VERSION ""

NS_ :

BS_:

BU_: NFCReader_Interior SCU NFCReader_Exterior

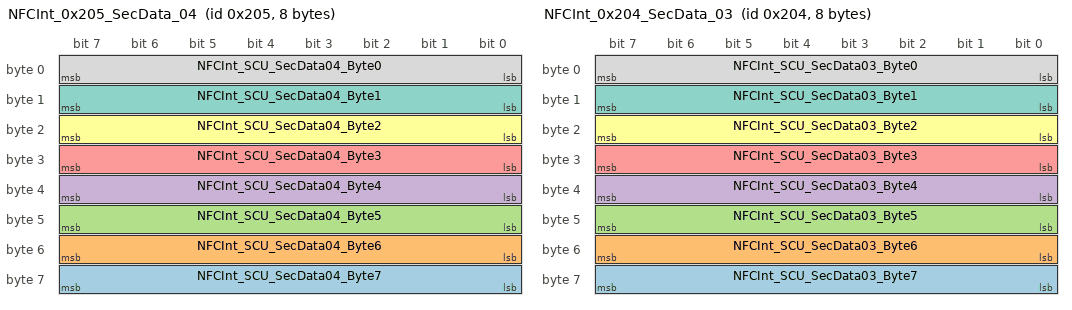
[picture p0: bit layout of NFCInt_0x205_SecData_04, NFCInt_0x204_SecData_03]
BO_ 517 NFCInt_0x205_SecData_04: 8 NFCReader_Interior
 SG_ NFCInt_SCU_SecData04_Byte7 : 56|8@1+ (1,0) [0|0] ""  SCU
 SG_ NFCInt_SCU_SecData04_Byte6 : 48|8@1+ (1,0) [0|0] ""  SCU
 SG_ NFCInt_SCU_SecData04_Byte5 : 40|8@1+ (1,0) [0|0] ""  SCU
 SG_ NFCInt_SCU_SecData04_Byte4 : 32|8@1+ (1,0) [0|0] ""  SCU
 SG_ NFCInt_SCU_SecData04_Byte3 : 24|8@1+ (1,0) [0|0] ""  SCU
 SG_ NFCInt_SCU_SecData04_Byte2 : 16|8@1+ (1,0) [0|0] ""  SCU
 SG_ NFCInt_SCU_SecData04_Byte1 : 8|8@1+ (1,0) [0|0] ""  SCU
 SG_ NFCInt_SCU_SecData04_Byte0 : 0|8@1+ (1,0) [0|0] ""  SCU

BO_ 516 NFCInt_0x204_SecData_03: 8 NFCReader_Interior
 SG_ NFCInt_SCU_SecData03_Byte7 : 56|8@1+ (1,0) [0|0] ""  SCU
 SG_ NFCInt_SCU_SecData03_Byte6 : 48|8@1+ (1,0) [0|0] ""  SCU
 SG_ NFCInt_SCU_SecData03_Byte5 : 40|8@1+ (1,0) [0|0] ""  SCU
 SG_ NFCInt_SCU_SecData03_Byte4 : 32|8@1+ (1,0) [0|0] ""  SCU
 SG_ NFCInt_SCU_SecData03_Byte3 : 24|8@1+ (1,0) [0|0] ""  SCU
 SG_ NFCInt_SCU_SecData03_Byte2 : 16|8@1+ (1,0) [0|0] ""  SCU
 SG_ NFCInt_SCU_SecData03_Byte1 : 8|8@1+ (1,0) [0|0] ""  SCU
 SG_ NFCInt_SCU_SecData03_Byte0 : 0|8@1+ (1,0) [0|0] ""  SCU

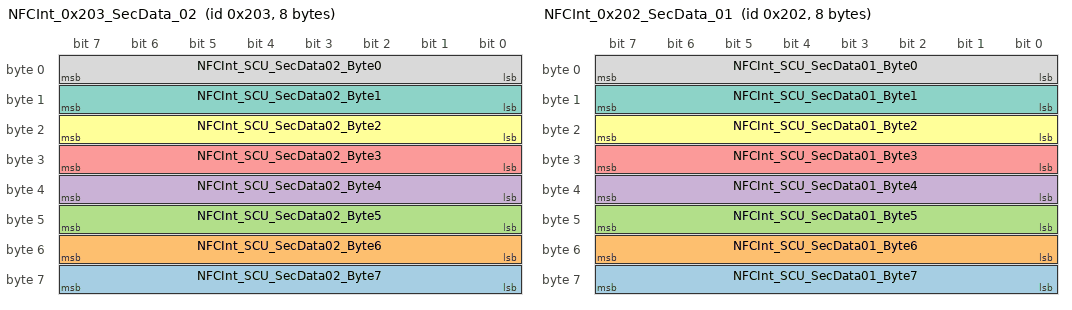
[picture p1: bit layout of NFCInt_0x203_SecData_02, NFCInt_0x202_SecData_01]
BO_ 515 NFCInt_0x203_SecData_02: 8 NFCReader_Interior
 SG_ NFCInt_SCU_SecData02_Byte7 : 56|8@1+ (1,0) [0|0] ""  SCU
 SG_ NFCInt_SCU_SecData02_Byte6 : 48|8@1+ (1,0) [0|0] ""  SCU
 SG_ NFCInt_SCU_SecData02_Byte5 : 40|8@1+ (1,0) [0|0] ""  SCU
 SG_ NFCInt_SCU_SecData02_Byte4 : 32|8@1+ (1,0) [0|0] ""  SCU
 SG_ NFCInt_SCU_SecData02_Byte3 : 24|8@1+ (1,0) [0|0] ""  SCU
 SG_ NFCInt_SCU_SecData02_Byte2 : 16|8@1+ (1,0) [0|0] ""  SCU
 SG_ NFCInt_SCU_SecData02_Byte1 : 8|8@1+ (1,0) [0|0] ""  SCU
 SG_ NFCInt_SCU_SecData02_Byte0 : 0|8@1+ (1,0) [0|0] ""  SCU

BO_ 514 NFCInt_0x202_SecData_01: 8 NFCReader_Interior
 SG_ NFCInt_SCU_SecData01_Byte7 : 56|8@1+ (1,0) [0|0] ""  SCU
 SG_ NFCInt_SCU_SecData01_Byte6 : 48|8@1+ (1,0) [0|0] ""  SCU
 SG_ NFCInt_SCU_SecData01_Byte5 : 40|8@1+ (1,0) [0|0] ""  SCU
 SG_ NFCInt_SCU_SecData01_Byte4 : 32|8@1+ (1,0) [0|0] ""  SCU
 SG_ NFCInt_SCU_SecData01_Byte3 : 24|8@1+ (1,0) [0|0] ""  SCU
 SG_ NFCInt_SCU_SecData01_Byte2 : 16|8@1+ (1,0) [0|0] ""  SCU
 SG_ NFCInt_SCU_SecData01_Byte1 : 8|8@1+ (1,0) [0|0] ""  SCU
 SG_ NFCInt_SCU_SecData01_Byte0 : 0|8@1+ (1,0) [0|0] ""  SCU

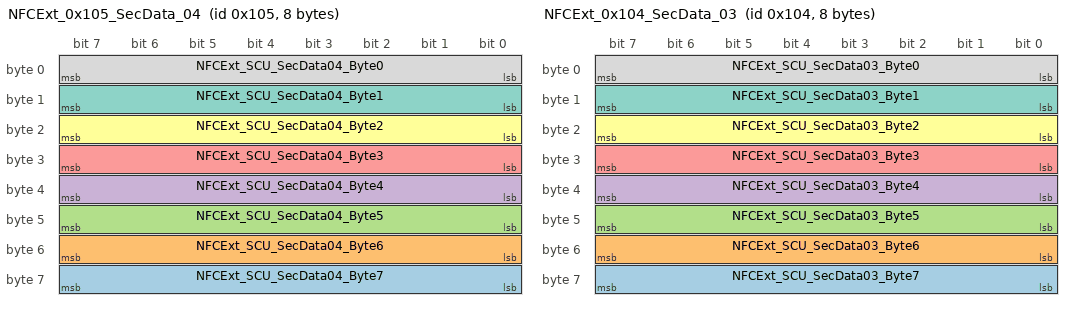
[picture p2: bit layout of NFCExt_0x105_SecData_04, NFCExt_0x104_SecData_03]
BO_ 261 NFCExt_0x105_SecData_04: 8 NFCReader_Exterior
 SG_ NFCExt_SCU_SecData04_Byte7 : 56|8@1+ (1,0) [0|0] ""  SCU
 SG_ NFCExt_SCU_SecData04_Byte6 : 48|8@1+ (1,0) [0|0] ""  SCU
 SG_ NFCExt_SCU_SecData04_Byte5 : 40|8@1+ (1,0) [0|0] ""  SCU
 SG_ NFCExt_SCU_SecData04_Byte4 : 32|8@1+ (1,0) [0|0] ""  SCU
 SG_ NFCExt_SCU_SecData04_Byte3 : 24|8@1+ (1,0) [0|0] ""  SCU
 SG_ NFCExt_SCU_SecData04_Byte2 : 16|8@1+ (1,0) [0|0] ""  SCU
 SG_ NFCExt_SCU_SecData04_Byte1 : 8|8@1+ (1,0) [0|0] ""  SCU
 SG_ NFCExt_SCU_SecData04_Byte0 : 0|8@1+ (1,0) [0|0] ""  SCU

BO_ 260 NFCExt_0x104_SecData_03: 8 NFCReader_Exterior
 SG_ NFCExt_SCU_SecData03_Byte7 : 56|8@1+ (1,0) [0|0] ""  SCU
 SG_ NFCExt_SCU_SecData03_Byte6 : 48|8@1+ (1,0) [0|0] ""  SCU
 SG_ NFCExt_SCU_SecData03_Byte5 : 40|8@1+ (1,0) [0|0] ""  SCU
 SG_ NFCExt_SCU_SecData03_Byte4 : 32|8@1+ (1,0) [0|0] ""  SCU
 SG_ NFCExt_SCU_SecData03_Byte3 : 24|8@1+ (1,0) [0|0] ""  SCU
 SG_ NFCExt_SCU_SecData03_Byte2 : 16|8@1+ (1,0) [0|0] ""  SCU
 SG_ NFCExt_SCU_SecData03_Byte1 : 8|8@1+ (1,0) [0|0] ""  SCU
 SG_ NFCExt_SCU_SecData03_Byte0 : 0|8@1+ (1,0) [0|0] ""  SCU

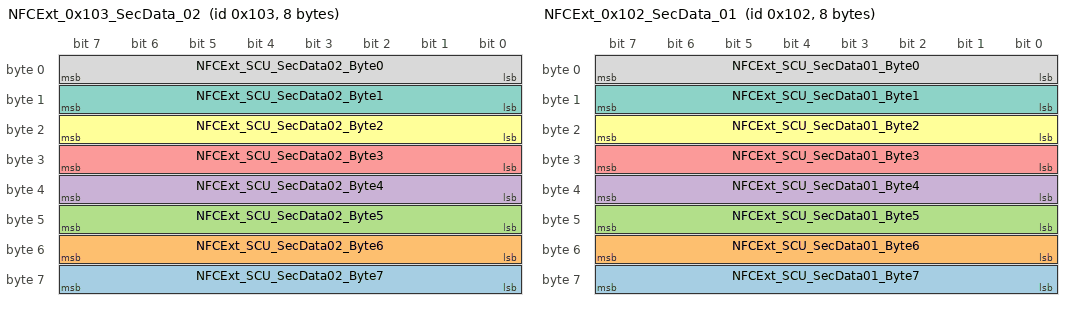
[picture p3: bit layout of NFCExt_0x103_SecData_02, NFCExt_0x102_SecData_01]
BO_ 259 NFCExt_0x103_SecData_02: 8 NFCReader_Exterior
 SG_ NFCExt_SCU_SecData02_Byte7 : 56|8@1+ (1,0) [0|0] ""  SCU
 SG_ NFCExt_SCU_SecData02_Byte6 : 48|8@1+ (1,0) [0|0] ""  SCU
 SG_ NFCExt_SCU_SecData02_Byte5 : 40|8@1+ (1,0) [0|0] ""  SCU
 SG_ NFCExt_SCU_SecData02_Byte4 : 32|8@1+ (1,0) [0|0] ""  SCU
 SG_ NFCExt_SCU_SecData02_Byte3 : 24|8@1+ (1,0) [0|0] ""  SCU
 SG_ NFCExt_SCU_SecData02_Byte2 : 16|8@1+ (1,0) [0|0] ""  SCU
 SG_ NFCExt_SCU_SecData02_Byte1 : 8|8@1+ (1,0) [0|0] ""  SCU
 SG_ NFCExt_SCU_SecData02_Byte0 : 0|8@1+ (1,0) [0|0] ""  SCU

BO_ 258 NFCExt_0x102_SecData_01: 8 NFCReader_Exterior
 SG_ NFCExt_SCU_SecData01_Byte7 : 56|8@1+ (1,0) [0|0] ""  SCU
 SG_ NFCExt_SCU_SecData01_Byte6 : 48|8@1+ (1,0) [0|0] ""  SCU
 SG_ NFCExt_SCU_SecData01_Byte5 : 40|8@1+ (1,0) [0|0] ""  SCU
 SG_ NFCExt_SCU_SecData01_Byte4 : 32|8@1+ (1,0) [0|0] ""  SCU
 SG_ NFCExt_SCU_SecData01_Byte3 : 24|8@1+ (1,0) [0|0] ""  SCU
 SG_ NFCExt_SCU_SecData01_Byte2 : 16|8@1+ (1,0) [0|0] ""  SCU
 SG_ NFCExt_SCU_SecData01_Byte1 : 8|8@1+ (1,0) [0|0] ""  SCU
 SG_ NFCExt_SCU_SecData01_Byte0 : 0|8@1+ (1,0) [0|0] ""  SCU

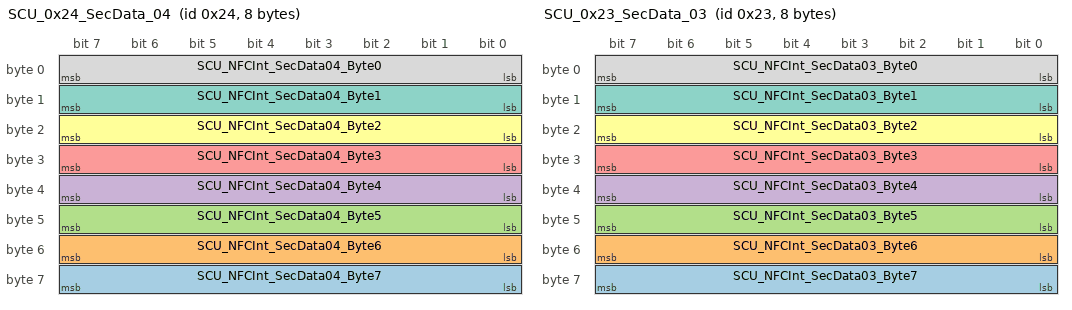
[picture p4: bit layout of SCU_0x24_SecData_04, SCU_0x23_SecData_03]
BO_ 36 SCU_0x24_SecData_04: 8 SCU
 SG_ SCU_NFCInt_SecData04_Byte7 : 56|8@1+ (1,0) [0|0] ""  NFCReader_Interior
 SG_ SCU_NFCInt_SecData04_Byte6 : 48|8@1+ (1,0) [0|0] ""  NFCReader_Interior
 SG_ SCU_NFCInt_SecData04_Byte5 : 40|8@1+ (1,0) [0|0] ""  NFCReader_Interior
 SG_ SCU_NFCInt_SecData04_Byte4 : 32|8@1+ (1,0) [0|0] ""  NFCReader_Interior
 SG_ SCU_NFCInt_SecData04_Byte3 : 24|8@1+ (1,0) [0|0] ""  NFCReader_Interior
 SG_ SCU_NFCInt_SecData04_Byte2 : 16|8@1+ (1,0) [0|0] ""  NFCReader_Interior
 SG_ SCU_NFCInt_SecData04_Byte1 : 8|8@1+ (1,0) [0|0] ""  NFCReader_Interior
 SG_ SCU_NFCInt_SecData04_Byte0 : 0|8@1+ (1,0) [0|0] ""  NFCReader_Interior

BO_ 35 SCU_0x23_SecData_03: 8 SCU
 SG_ SCU_NFCInt_SecData03_Byte7 : 56|8@1+ (1,0) [0|0] ""  NFCReader_Interior
 SG_ SCU_NFCInt_SecData03_Byte6 : 48|8@1+ (1,0) [0|0] ""  NFCReader_Interior
 SG_ SCU_NFCInt_SecData03_Byte5 : 40|8@1+ (1,0) [0|0] ""  NFCReader_Interior
 SG_ SCU_NFCInt_SecData03_Byte4 : 32|8@1+ (1,0) [0|0] ""  NFCReader_Interior
 SG_ SCU_NFCInt_SecData03_Byte3 : 24|8@1+ (1,0) [0|0] ""  NFCReader_Interior
 SG_ SCU_NFCInt_SecData03_Byte2 : 16|8@1+ (1,0) [0|0] ""  NFCReader_Interior
 SG_ SCU_NFCInt_SecData03_Byte1 : 8|8@1+ (1,0) [0|0] ""  NFCReader_Interior
 SG_ SCU_NFCInt_SecData03_Byte0 : 0|8@1+ (1,0) [0|0] ""  NFCReader_Interior

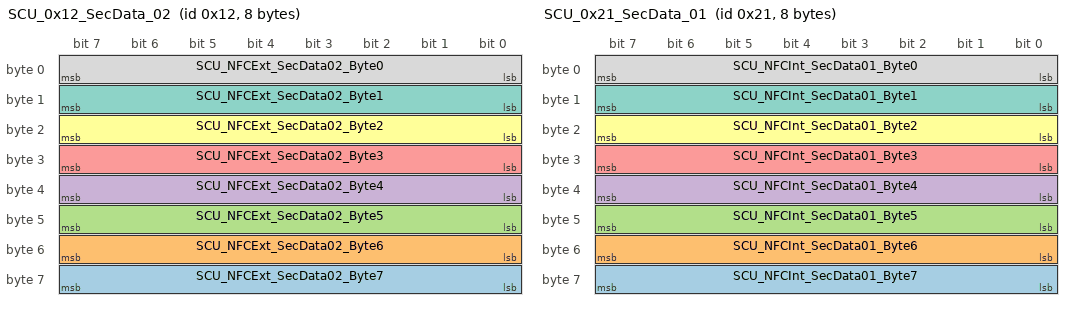
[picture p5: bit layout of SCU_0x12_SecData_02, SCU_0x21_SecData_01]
BO_ 18 SCU_0x12_SecData_02: 8 SCU
 SG_ SCU_NFCExt_SecData02_Byte7 : 56|8@1+ (1,0) [0|0] ""  NFCReader_Exterior
 SG_ SCU_NFCExt_SecData02_Byte6 : 48|8@1+ (1,0) [0|0] ""  NFCReader_Exterior
 SG_ SCU_NFCExt_SecData02_Byte5 : 40|8@1+ (1,0) [0|0] ""  NFCReader_Exterior
 SG_ SCU_NFCExt_SecData02_Byte4 : 32|8@1+ (1,0) [0|0] ""  NFCReader_Exterior
 SG_ SCU_NFCExt_SecData02_Byte3 : 24|8@1+ (1,0) [0|0] ""  NFCReader_Exterior
 SG_ SCU_NFCExt_SecData02_Byte2 : 16|8@1+ (1,0) [0|0] ""  NFCReader_Exterior
 SG_ SCU_NFCExt_SecData02_Byte1 : 8|8@1+ (1,0) [0|0] ""  NFCReader_Exterior
 SG_ SCU_NFCExt_SecData02_Byte0 : 0|8@1+ (1,0) [0|0] ""  NFCReader_Exterior

BO_ 33 SCU_0x21_SecData_01: 8 SCU
 SG_ SCU_NFCInt_SecData01_Byte7 : 56|8@1+ (1,0) [0|0] ""  NFCReader_Interior
 SG_ SCU_NFCInt_SecData01_Byte6 : 48|8@1+ (1,0) [0|0] ""  NFCReader_Interior
 SG_ SCU_NFCInt_SecData01_Byte5 : 40|8@1+ (1,0) [0|0] ""  NFCReader_Interior
 SG_ SCU_NFCInt_SecData01_Byte4 : 32|8@1+ (1,0) [0|0] ""  NFCReader_Interior
 SG_ SCU_NFCInt_SecData01_Byte3 : 24|8@1+ (1,0) [0|0] ""  NFCReader_Interior
 SG_ SCU_NFCInt_SecData01_Byte2 : 16|8@1+ (1,0) [0|0] ""  NFCReader_Interior
 SG_ SCU_NFCInt_SecData01_Byte1 : 8|8@1+ (1,0) [0|0] ""  NFCReader_Interior
 SG_ SCU_NFCInt_SecData01_Byte0 : 0|8@1+ (1,0) [0|0] ""  NFCReader_Interior

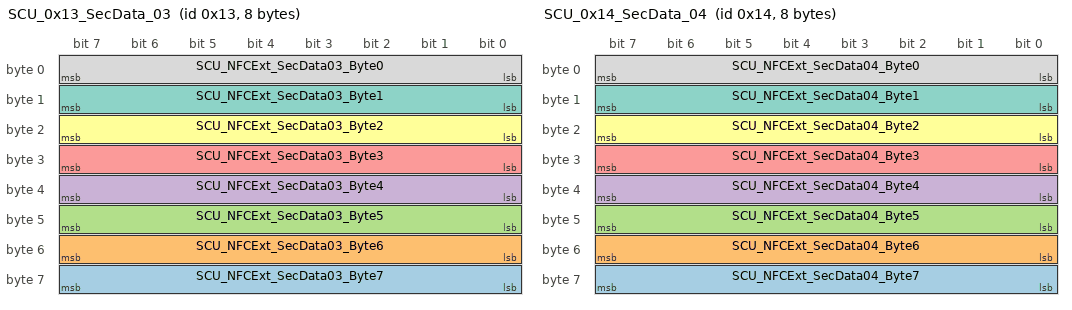
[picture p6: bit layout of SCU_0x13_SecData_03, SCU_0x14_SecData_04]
BO_ 19 SCU_0x13_SecData_03: 8 SCU
 SG_ SCU_NFCExt_SecData03_Byte7 : 56|8@1+ (1,0) [0|0] ""  NFCReader_Exterior
 SG_ SCU_NFCExt_SecData03_Byte6 : 48|8@1+ (1,0) [0|0] ""  NFCReader_Exterior
 SG_ SCU_NFCExt_SecData03_Byte5 : 40|8@1+ (1,0) [0|0] ""  NFCReader_Exterior
 SG_ SCU_NFCExt_SecData03_Byte4 : 32|8@1+ (1,0) [0|0] ""  NFCReader_Exterior
 SG_ SCU_NFCExt_SecData03_Byte3 : 24|8@1+ (1,0) [0|0] ""  NFCReader_Exterior
 SG_ SCU_NFCExt_SecData03_Byte2 : 16|8@1+ (1,0) [0|0] ""  NFCReader_Exterior
 SG_ SCU_NFCExt_SecData03_Byte1 : 8|8@1+ (1,0) [0|0] ""  NFCReader_Exterior
 SG_ SCU_NFCExt_SecData03_Byte0 : 0|8@1+ (1,0) [0|0] ""  NFCReader_Exterior

BO_ 20 SCU_0x14_SecData_04: 8 SCU
 SG_ SCU_NFCExt_SecData04_Byte7 : 56|8@1+ (1,0) [0|0] ""  NFCReader_Exterior
 SG_ SCU_NFCExt_SecData04_Byte6 : 48|8@1+ (1,0) [0|0] ""  NFCReader_Exterior
 SG_ SCU_NFCExt_SecData04_Byte5 : 40|8@1+ (1,0) [0|0] ""  NFCReader_Exterior
 SG_ SCU_NFCExt_SecData04_Byte4 : 32|8@1+ (1,0) [0|0] ""  NFCReader_Exterior
 SG_ SCU_NFCExt_SecData04_Byte3 : 24|8@1+ (1,0) [0|0] ""  NFCReader_Exterior
 SG_ SCU_NFCExt_SecData04_Byte2 : 16|8@1+ (1,0) [0|0] ""  NFCReader_Exterior
 SG_ SCU_NFCExt_SecData04_Byte1 : 8|8@1+ (1,0) [0|0] ""  NFCReader_Exterior
 SG_ SCU_NFCExt_SecData04_Byte0 : 0|8@1+ (1,0) [0|0] ""  NFCReader_Exterior

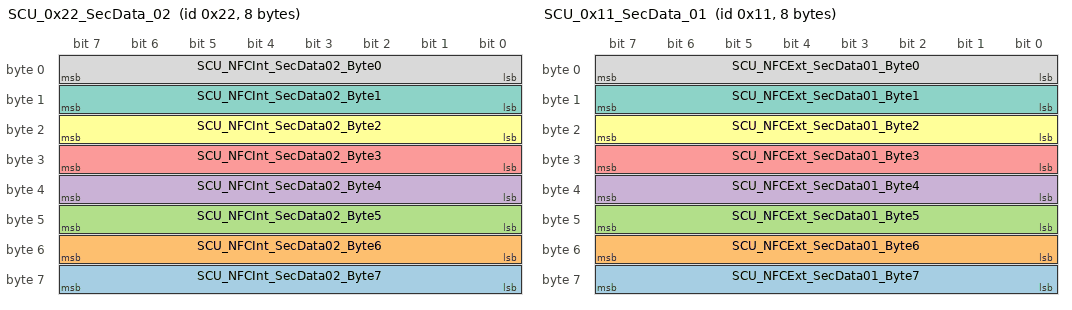
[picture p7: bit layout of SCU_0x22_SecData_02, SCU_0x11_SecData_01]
BO_ 34 SCU_0x22_SecData_02: 8 SCU
 SG_ SCU_NFCInt_SecData02_Byte7 : 56|8@1+ (1,0) [0|0] ""  NFCReader_Interior
 SG_ SCU_NFCInt_SecData02_Byte6 : 48|8@1+ (1,0) [0|0] ""  NFCReader_Interior
 SG_ SCU_NFCInt_SecData02_Byte5 : 40|8@1+ (1,0) [0|0] ""  NFCReader_Interior
 SG_ SCU_NFCInt_SecData02_Byte4 : 32|8@1+ (1,0) [0|0] ""  NFCReader_Interior
 SG_ SCU_NFCInt_SecData02_Byte3 : 24|8@1+ (1,0) [0|0] ""  NFCReader_Interior
 SG_ SCU_NFCInt_SecData02_Byte2 : 16|8@1+ (1,0) [0|0] ""  NFCReader_Interior
 SG_ SCU_NFCInt_SecData02_Byte1 : 8|8@1+ (1,0) [0|0] ""  NFCReader_Interior
 SG_ SCU_NFCInt_SecData02_Byte0 : 0|8@1+ (1,0) [0|0] ""  NFCReader_Interior

BO_ 17 SCU_0x11_SecData_01: 8 SCU
 SG_ SCU_NFCExt_SecData01_Byte7 : 56|8@1+ (1,0) [0|0] ""  NFCReader_Exterior
 SG_ SCU_NFCExt_SecData01_Byte6 : 48|8@1+ (1,0) [0|0] ""  NFCReader_Exterior
 SG_ SCU_NFCExt_SecData01_Byte5 : 40|8@1+ (1,0) [0|0] ""  NFCReader_Exterior
 SG_ SCU_NFCExt_SecData01_Byte4 : 32|8@1+ (1,0) [0|0] ""  NFCReader_Exterior
 SG_ SCU_NFCExt_SecData01_Byte3 : 24|8@1+ (1,0) [0|0] ""  NFCReader_Exterior
 SG_ SCU_NFCExt_SecData01_Byte2 : 16|8@1+ (1,0) [0|0] ""  NFCReader_Exterior
 SG_ SCU_NFCExt_SecData01_Byte1 : 8|8@1+ (1,0) [0|0] ""  NFCReader_Exterior
 SG_ SCU_NFCExt_SecData01_Byte0 : 0|8@1+ (1,0) [0|0] ""  NFCReader_Exterior

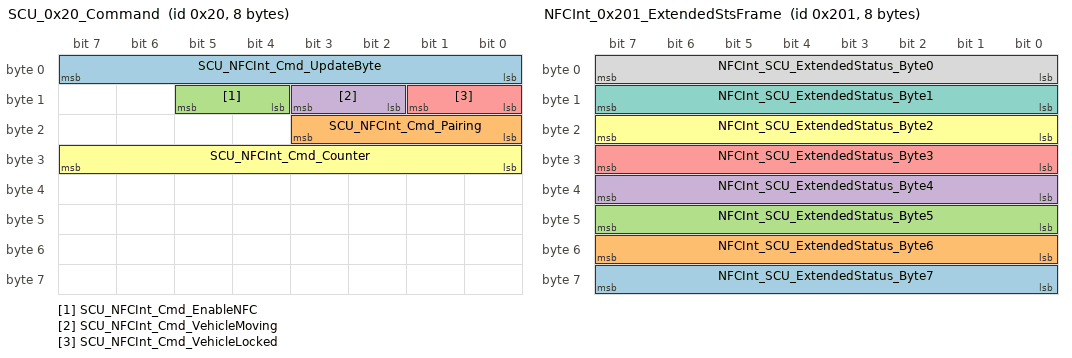
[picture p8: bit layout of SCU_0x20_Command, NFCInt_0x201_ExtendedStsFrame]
BO_ 32 SCU_0x20_Command: 8 SCU
 SG_ SCU_NFCInt_Cmd_UpdateByte : 0|8@1+ (1,0) [0|0] "" Vector__XXX
 SG_ SCU_NFCInt_Cmd_Pairing : 16|4@1+ (1,0) [0|0] "" Vector__XXX
 SG_ SCU_NFCInt_Cmd_EnableNFC : 12|2@1+ (1,0) [0|0] "" Vector__XXX
 SG_ SCU_NFCInt_Cmd_VehicleMoving : 10|2@1+ (1,0) [0|3] ""  NFCReader_Interior
 SG_ SCU_NFCInt_Cmd_VehicleLocked : 8|2@1+ (1,0) [0|3] ""  NFCReader_Interior
 SG_ SCU_NFCInt_Cmd_Counter : 24|8@1+ (1,0) [0|255] ""  NFCReader_Interior

BO_ 513 NFCInt_0x201_ExtendedStsFrame: 8 NFCReader_Interior
 SG_ NFCInt_SCU_ExtendedStatus_Byte7 : 56|8@1+ (1,0) [0|0] ""  SCU
 SG_ NFCInt_SCU_ExtendedStatus_Byte6 : 48|8@1+ (1,0) [0|0] ""  SCU
 SG_ NFCInt_SCU_ExtendedStatus_Byte5 : 40|8@1+ (1,0) [0|0] ""  SCU
 SG_ NFCInt_SCU_ExtendedStatus_Byte4 : 32|8@1+ (1,0) [0|0] ""  SCU
 SG_ NFCInt_SCU_ExtendedStatus_Byte3 : 24|8@1+ (1,0) [0|0] ""  SCU
 SG_ NFCInt_SCU_ExtendedStatus_Byte2 : 16|8@1+ (1,0) [0|0] ""  SCU
 SG_ NFCInt_SCU_ExtendedStatus_Byte1 : 8|8@1+ (1,0) [0|0] ""  SCU
 SG_ NFCInt_SCU_ExtendedStatus_Byte0 : 0|8@1+ (1,0) [0|0] ""  SCU

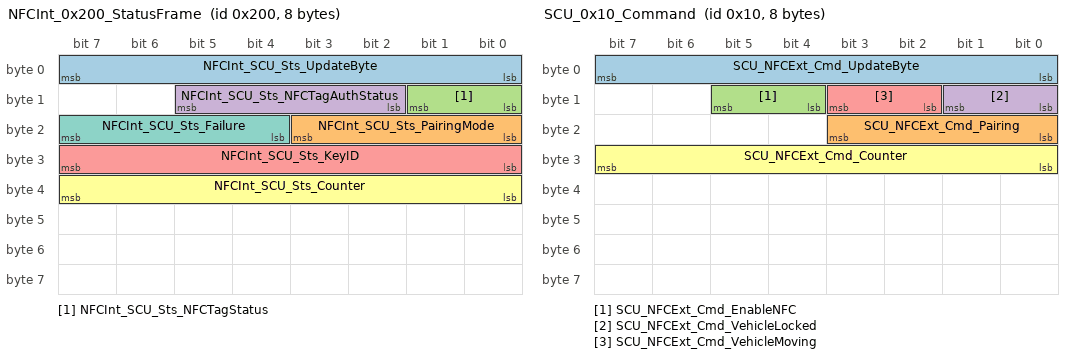
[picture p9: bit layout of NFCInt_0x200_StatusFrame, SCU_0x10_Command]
BO_ 512 NFCInt_0x200_StatusFrame: 8 NFCReader_Interior
 SG_ NFCInt_SCU_Sts_UpdateByte : 0|8@1+ (1,0) [0|0] "" Vector__XXX
 SG_ NFCInt_SCU_Sts_PairingMode : 16|4@1+ (1,0) [0|0] "" Vector__XXX
 SG_ NFCInt_SCU_Sts_NFCTagStatus : 8|2@1+ (1,0) [0|0] "" Vector__XXX
 SG_ NFCInt_SCU_Sts_NFCTagAuthStatus : 10|4@1+ (1,0) [0|0] "" Vector__XXX
 SG_ NFCInt_SCU_Sts_KeyID : 24|8@1+ (1,0) [0|0] "" Vector__XXX
 SG_ NFCInt_SCU_Sts_Counter : 32|8@1+ (1,0) [0|255] ""  SCU
 SG_ NFCInt_SCU_Sts_Failure : 20|4@1+ (1,0) [0|15] ""  SCU

BO_ 16 SCU_0x10_Command: 8 SCU
 SG_ SCU_NFCExt_Cmd_UpdateByte : 0|8@1+ (1,0) [0|0] "" Vector__XXX
 SG_ SCU_NFCExt_Cmd_Pairing : 16|4@1+ (1,0) [0|0] "" Vector__XXX
 SG_ SCU_NFCExt_Cmd_EnableNFC : 12|2@1+ (1,0) [0|0] "" Vector__XXX
 SG_ SCU_NFCExt_Cmd_VehicleLocked : 8|2@1+ (1,0) [0|3] ""  NFCReader_Exterior
 SG_ SCU_NFCExt_Cmd_VehicleMoving : 10|2@1+ (1,0) [0|3] ""  NFCReader_Exterior
 SG_ SCU_NFCExt_Cmd_Counter : 24|8@1+ (1,0) [0|255] ""  NFCReader_Exterior

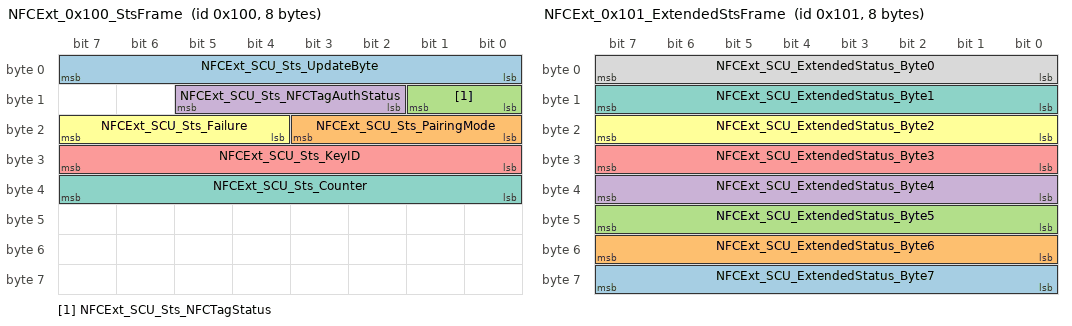
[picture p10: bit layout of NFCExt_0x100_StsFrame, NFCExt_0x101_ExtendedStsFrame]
BO_ 256 NFCExt_0x100_StsFrame: 8 NFCReader_Exterior
 SG_ NFCExt_SCU_Sts_UpdateByte : 0|8@1+ (1,0) [0|0] "" Vector__XXX
 SG_ NFCExt_SCU_Sts_PairingMode : 16|4@1+ (1,0) [0|0] "" Vector__XXX
 SG_ NFCExt_SCU_Sts_NFCTagStatus : 8|2@1+ (1,0) [0|0] "" Vector__XXX
 SG_ NFCExt_SCU_Sts_NFCTagAuthStatus : 10|4@1+ (1,0) [0|0] "" Vector__XXX
 SG_ NFCExt_SCU_Sts_KeyID : 24|8@1+ (1,0) [0|0] "" Vector__XXX
 SG_ NFCExt_SCU_Sts_Failure : 20|4@1+ (1,0) [0|15] ""  SCU
 SG_ NFCExt_SCU_Sts_Counter : 32|8@1+ (1,0) [0|255] ""  SCU

BO_ 257 NFCExt_0x101_ExtendedStsFrame: 8 NFCReader_Exterior
 SG_ NFCExt_SCU_ExtendedStatus_Byte7 : 56|8@1+ (1,0) [0|0] ""  SCU
 SG_ NFCExt_SCU_ExtendedStatus_Byte6 : 48|8@1+ (1,0) [0|0] ""  SCU
 SG_ NFCExt_SCU_ExtendedStatus_Byte5 : 40|8@1+ (1,0) [0|0] ""  SCU
 SG_ NFCExt_SCU_ExtendedStatus_Byte4 : 32|8@1+ (1,0) [0|0] ""  SCU
 SG_ NFCExt_SCU_ExtendedStatus_Byte3 : 24|8@1+ (1,0) [0|0] ""  SCU
 SG_ NFCExt_SCU_ExtendedStatus_Byte2 : 16|8@1+ (1,0) [0|0] ""  SCU
 SG_ NFCExt_SCU_ExtendedStatus_Byte1 : 8|8@1+ (1,0) [0|0] ""  SCU
 SG_ NFCExt_SCU_ExtendedStatus_Byte0 : 0|8@1+ (1,0) [0|0] ""  SCU

CM_ SG_ 517 NFCInt_SCU_SecData04_Byte7 "MSB for Arrays";
CM_ SG_ 517 NFCInt_SCU_SecData04_Byte0 "LSB for Arrays";
CM_ SG_ 516 NFCInt_SCU_SecData03_Byte0 "LSB for Arrays";
CM_ SG_ 515 NFCInt_SCU_SecData02_Byte7 "MSB for Arrays";
CM_ SG_ 515 NFCInt_SCU_SecData02_Byte0 "LSB for Arrays";
CM_ SG_ 514 NFCInt_SCU_SecData01_Byte7 "MSB for Arrays";
CM_ SG_ 514 NFCInt_SCU_SecData01_Byte0 "LSB for Arrays";
CM_ SG_ 261 NFCExt_SCU_SecData04_Byte7 "MSB for Arrays";
CM_ SG_ 261 NFCExt_SCU_SecData04_Byte0 "LSB for Arrays";
CM_ SG_ 260 NFCExt_SCU_SecData03_Byte7 "MSB for Arrays";
CM_ SG_ 260 NFCExt_SCU_SecData03_Byte0 "LSB for Arrays";
CM_ SG_ 259 NFCExt_SCU_SecData02_Byte7 "MSB for Arrays";
CM_ SG_ 259 NFCExt_SCU_SecData02_Byte0 "LSB for Arrays";
CM_ SG_ 258 NFCExt_SCU_SecData01_Byte7 "MSB for Arrays";
CM_ SG_ 258 NFCExt_SCU_SecData01_Byte0 "LSB for Arrays";
CM_ SG_ 36 SCU_NFCInt_SecData04_Byte7 "MSB for Arrays";
CM_ SG_ 36 SCU_NFCInt_SecData04_Byte0 "LSB for Arrays";
CM_ SG_ 35 SCU_NFCInt_SecData03_Byte7 "MSB for Arrays";
CM_ SG_ 35 SCU_NFCInt_SecData03_Byte0 "LSB for Arrays";
CM_ SG_ 18 SCU_NFCExt_SecData02_Byte7 "MSB for Arrays";
CM_ SG_ 18 SCU_NFCExt_SecData02_Byte0 "LSB for Arrays";
CM_ SG_ 33 SCU_NFCInt_SecData01_Byte7 "MSB for Arrays";
CM_ SG_ 33 SCU_NFCInt_SecData01_Byte0 "LSB for Arrays";
CM_ SG_ 19 SCU_NFCExt_SecData03_Byte7 "MSB for Arrays";
CM_ SG_ 19 SCU_NFCExt_SecData03_Byte0 "LSB for Arrays";
CM_ SG_ 20 SCU_NFCExt_SecData04_Byte7 "MSB for Arrays";
CM_ SG_ 20 SCU_NFCExt_SecData04_Byte0 "LSB for Arrays";
CM_ SG_ 34 SCU_NFCInt_SecData02_Byte7 "MSB for Arrays";
CM_ SG_ 34 SCU_NFCInt_SecData02_Byte0 "LSB for Arrays";
CM_ SG_ 17 SCU_NFCExt_SecData01_Byte7 "MSB for Arrays";
CM_ SG_ 17 SCU_NFCExt_SecData01_Byte3 "LSB for Arrays";
CM_ SG_ 17 SCU_NFCExt_SecData01_Byte0 "LSB for Arrays";
CM_ SG_ 32 SCU_NFCInt_Cmd_VehicleMoving "Rear Left Door Vehicle Moving Signal";
CM_ SG_ 32 SCU_NFCInt_Cmd_VehicleLocked "Rear Left Door Vehicle Locked Signal";
CM_ SG_ 32 SCU_NFCInt_Cmd_Counter "Rear Left Door Command Message Counter - Value has to be incremented on each transmission of the command frame. Only frames with consecutive command counter values are valid.";
CM_ BO_ 513 "Internal signals, not used in normal operation";
CM_ SG_ 512 NFCInt_SCU_Sts_Counter "Rear Left Door Status Message Counter";
CM_ SG_ 512 NFCInt_SCU_Sts_Failure "Rear Left Door Latch Failure status";
CM_ SG_ 16 SCU_NFCExt_Cmd_VehicleLocked "Front Left Door Vehicle Locked Signal";
CM_ SG_ 16 SCU_NFCExt_Cmd_VehicleMoving "Front Left Door Vehicle Moving Signal";
CM_ SG_ 16 SCU_NFCExt_Cmd_Counter "Front Left Door Command Message Counter - Value has to be incremented on each transmission of the command frame. Only frames with consecutive command counter values are valid.";
CM_ SG_ 256 NFCExt_SCU_Sts_Failure "Front Left Door Latch Failure status";
CM_ SG_ 256 NFCExt_SCU_Sts_Counter "Front Left Door Status Message Counter";
CM_ BO_ 257 "Internal signals, not used in normal operation";
BA_DEF_ BO_  "GenMsgNrOfRepetition" INT 0 0;
BA_DEF_ BO_  "GenMsgCycleTime" INT 0 0;
BA_DEF_ BO_  "GenMsgSendType" ENUM  "Cyclic","NotUsed","NotUsed","NotUsed","NotUsed","NotUsed","NotUsed","IfActive","NoMsgSendType","NotUsed";
BA_DEF_ SG_  "GenSigStartValue" INT 0 0;
BA_DEF_ SG_  "GenSigSendType" ENUM  "Cyclic","OnWrite","OnWriteWithRepetition","OnChange","OnChangeWithRepetition","IfActive","IfActiveWithRepetition","NoSigSendType","NotUsed","NotUsed","NotUsed","NotUsed","NotUsed";
BA_DEF_  "Baudrate" INT 0 1000000;
BA_DEF_  "BusType" STRING ;
BA_DEF_  "NmType" STRING ;
BA_DEF_  "Manufacturer" STRING ;
BA_DEF_ BU_  "NodeLayerModules" STRING ;
BA_DEF_ BU_  "NmStationAddress" HEX 0 255;
BA_DEF_  "NmAsrWaitBusSleepTime" INT 0 65535;
BA_DEF_  "NmAsrTimeoutTime" INT 1 65535;
BA_DEF_  "NmAsrRepeatMessageTime" INT 0 65535;
BA_DEF_ BU_  "NmAsrNodeIdentifier" HEX 0 255;
BA_DEF_  "NmAsrMessageCount" INT 1 256;
BA_DEF_ BU_  "NmAsrCanMsgReducedTime" INT 1 65535;
BA_DEF_  "NmAsrCanMsgCycleTime" INT 1 65535;
BA_DEF_  "NmAsrBaseAddress" HEX 0 2047;
BA_DEF_  "DBName" STRING ;
BA_DEF_DEF_  "GenMsgNrOfRepetition" 0;
BA_DEF_DEF_  "GenMsgCycleTime" 0;
BA_DEF_DEF_  "GenMsgSendType" "Cyclic";
BA_DEF_DEF_  "GenSigStartValue" 0;
BA_DEF_DEF_  "GenSigSendType" "Cyclic";
BA_DEF_DEF_  "Baudrate" 500000;
BA_DEF_DEF_  "BusType" "";
BA_DEF_DEF_  "NmType" "";
BA_DEF_DEF_  "Manufacturer" "Vector";
BA_DEF_DEF_  "NodeLayerModules" " ";
BA_DEF_DEF_  "NmStationAddress" 0;
BA_DEF_DEF_  "NmAsrWaitBusSleepTime" 1500;
BA_DEF_DEF_  "NmAsrTimeoutTime" 2000;
BA_DEF_DEF_  "NmAsrRepeatMessageTime" 3200;
BA_DEF_DEF_  "NmAsrNodeIdentifier" 50;
BA_DEF_DEF_  "NmAsrMessageCount" 128;
BA_DEF_DEF_  "NmAsrCanMsgReducedTime" 320;
BA_DEF_DEF_  "NmAsrCanMsgCycleTime" 640;
BA_DEF_DEF_  "NmAsrBaseAddress" 1280;
BA_DEF_DEF_  "DBName" "";
BA_ "NmType" "NmAsr";
BA_ "BusType" "CAN";
BA_ "NmAsrWaitBusSleepTime" 2000;
BA_ "DBName" "FM29_NFC_Readers_CAN_v10";
BA_ "NmStationAddress" BU_ NFCReader_Interior 43;
BA_ "NmStationAddress" BU_ SCU 41;
BA_ "NmStationAddress" BU_ NFCReader_Exterior 42;
BA_ "GenMsgSendType" BO_ 517 8;
BA_ "GenMsgNrOfRepetition" BO_ 517 3;
BA_ "GenMsgSendType" BO_ 516 8;
BA_ "GenMsgNrOfRepetition" BO_ 516 3;
BA_ "GenMsgSendType" BO_ 515 8;
BA_ "GenMsgNrOfRepetition" BO_ 515 3;
BA_ "GenMsgSendType" BO_ 514 8;
BA_ "GenMsgNrOfRepetition" BO_ 514 3;
BA_ "GenMsgSendType" BO_ 261 8;
BA_ "GenMsgNrOfRepetition" BO_ 261 3;
BA_ "GenMsgSendType" BO_ 260 8;
BA_ "GenMsgNrOfRepetition" BO_ 260 3;
BA_ "GenMsgSendType" BO_ 259 8;
BA_ "GenMsgNrOfRepetition" BO_ 259 3;
BA_ "GenMsgSendType" BO_ 258 8;
BA_ "GenMsgNrOfRepetition" BO_ 258 3;
BA_ "GenMsgSendType" BO_ 36 8;
BA_ "GenMsgNrOfRepetition" BO_ 36 3;
BA_ "GenMsgSendType" BO_ 35 8;
BA_ "GenMsgNrOfRepetition" BO_ 35 3;
BA_ "GenMsgSendType" BO_ 18 8;
BA_ "GenMsgNrOfRepetition" BO_ 18 3;
BA_ "GenMsgSendType" BO_ 33 8;
BA_ "GenMsgNrOfRepetition" BO_ 33 3;
BA_ "GenMsgSendType" BO_ 19 8;
BA_ "GenMsgNrOfRepetition" BO_ 19 3;
BA_ "GenMsgSendType" BO_ 20 8;
BA_ "GenMsgNrOfRepetition" BO_ 20 3;
BA_ "GenMsgSendType" BO_ 34 8;
BA_ "GenMsgNrOfRepetition" BO_ 34 3;
BA_ "GenMsgSendType" BO_ 17 8;
BA_ "GenMsgNrOfRepetition" BO_ 17 3;
BA_ "GenMsgCycleTime" BO_ 32 10;
BA_ "GenMsgCycleTime" BO_ 513 20;
BA_ "GenMsgCycleTime" BO_ 512 15;
BA_ "GenMsgCycleTime" BO_ 16 10;
BA_ "GenMsgCycleTime" BO_ 256 15;
BA_ "GenMsgCycleTime" BO_ 257 20;
VAL_ 32 SCU_NFCInt_Cmd_VehicleMoving 3 "in motion" 2 "static" 0 " default (in motion)" ;
VAL_ 32 SCU_NFCInt_Cmd_VehicleLocked 3 "locked" 2 "unlocked" 0 " default (locked)" ;
VAL_ 512 NFCInt_SCU_Sts_Failure 15 "default (no fault)" 14 "failure - failed to clinch" 13 "failure - motor stalled" 12 "failure - clinch obstructed" 11 "failure - door iced" 10 "failure - operation denied" 9 "failure - over voltage" 8 "failure - under voltage" 7 "failure - over temperature" 6 "failure - invalid value" 5 "failure - encoder feedback" 4 "failure - claw sensor failure" 3 "failure - invalid value" 2 "failure - invalid value" 1 "failure - actuator failure" 0 "no fault" ;
VAL_ 16 SCU_NFCExt_Cmd_VehicleLocked 3 "locked" 2 "unlocked" 0 " default (locked)" ;
VAL_ 16 SCU_NFCExt_Cmd_VehicleMoving 3 "in motion" 2 "static" 0 " default (in motion)" ;
VAL_ 256 NFCExt_SCU_Sts_Failure 15 "default (no fault)" 14 "failure - failed to clinch" 13 "failure - motor stalled" 12 "failure - clinch obstructed" 11 "failure - door iced" 10 "failure - operation denied" 9 "failure - over voltage" 8 "failure - under voltage" 7 "failure - over temperature" 6 "failure - invalid value" 5 "failure - encoder feedback" 4 "failure - claw sensor failure" 3 "failure - invalid value" 2 "failure - invalid value" 1 "failure - actuator failure" 0 "no fault" ;
